# DA1470x register map
Vendor: Dialog; Series: DA1470x; File version: 1.2
CPU: CM33 r0p2, little endian, MPU, FPU, DSP, VTOR, 4 interrupt priority bits
Registers are 32-bit, read-write, reset 0x0 unless marked. A register's access mark holds for its fields unless they carry their own. Offsets are from the block's base; [hi:lo] are bit positions.

## ANAMISC_BIF — ANAMISC_BIF registers
Base 0x50050600
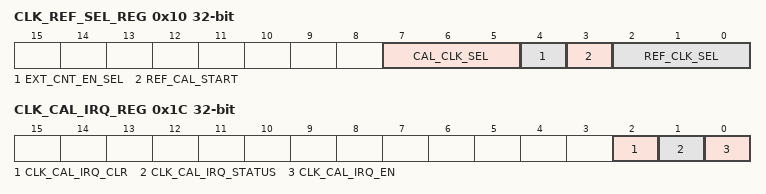
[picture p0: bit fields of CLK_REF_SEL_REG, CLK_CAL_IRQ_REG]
0x10 CLK_REF_SEL_REG — Select clock for oscillator calibration
  [7:5] CAL_CLK_SEL — Select calibration clock input to be used in calibration: 0x0 : DIVN clock 0x1 : RCLP 0x2 : RCHS 0x3 : XTAL32K 0x4 : RCOSC 0x5, 0x6 and 0x7: Reserved
  [4] EXT_CNT_EN_SEL — 0 : Enable XTAL_CNT counter by the REF_CLK selected by REF_CLK_SEL. 1 : Enable XTAL_CNT counter from an external input.
  [3] REF_CAL_START — Writing a '1' starts a calibration. This bit is cleared when calibration is finished, and CLK_REF_VAL is ready.
  [2:0] REF_CLK_SEL — Select reference clock input for calibration: 0x0 : RCLP 0x1 : RCHS 0x2 : XTAL32K 0x3 : RCX 0x4 : RCOSC 0x5 : DIVN clock
0x14 CLK_REF_CNT_REG — Count value for oscillator calibration
  [15:0] REF_CNT_VAL — Indicates the calibration time, with a decrement counter to 1.
0x18 CLK_REF_VAL_REG (reset mask 0x7FFFFFFF) — DIVN reference cycles, lower 16 bits
  [31:0] XTAL_CNT_VAL ro — Returns the number of DIVN clock cycles counted during the calibration time, defined with REF_CNT_VAL
0x1C CLK_CAL_IRQ_REG — Select clock for oscillator calibration
  [2] CLK_CAL_IRQ_CLR — Clear the IRQ. 1: Clear the IRQ 0: No effect. Read out 0 always.
  [1] CLK_CAL_IRQ_STATUS ro — Shows the IRQ bit status.
  [0] CLK_CAL_IRQ_EN — Enable clk calibration IRQ. 0: Disabled. 1*: Enabled. *Note: If IRQ feature is enabled, every calibration should be started by setting CLK_REF_SEL_REG[REF_CAL_START] to 1.

## CRG_AUD — CRG_AUD registers
Base 0x50030000
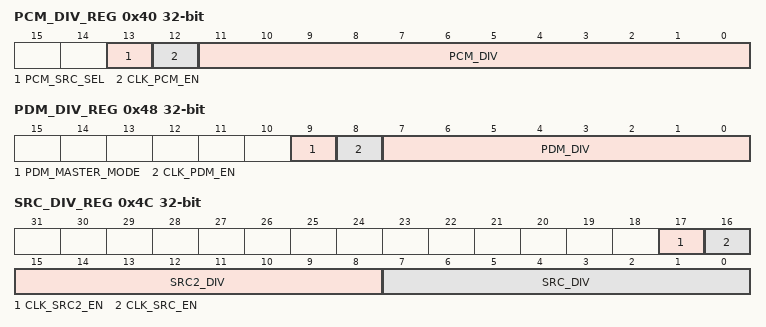
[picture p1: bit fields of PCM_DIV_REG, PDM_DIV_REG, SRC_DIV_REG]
0x40 PCM_DIV_REG — PCM divider and enables
  [13] PCM_SRC_SEL — Selects the clock source 1 = DIV1 clock 0 = DIVN clock
  [12] CLK_PCM_EN — Enable for the internally generated PCM clock The PCM_DIV must be set before or together with CLK_PCM_EN.
  [11:0] PCM_DIV — PCM clock divider. Minimum value is 0x2.
0x44 PCM_FDIV_REG — PCM fractional division register
  [15:0] PCM_FDIV — These bits define the fractional division part of the PCM clock. The left most '1' defines the denominator, the number of '1' bits define the numerator. E.g. 0x0110 means 2/9, with a distribution of 1.0001.0000 0xfeee means 13/16, with a distribution of 1111.1110.1110.1110
0x48 PDM_DIV_REG — PDM divider and enables
  [9] PDM_MASTER_MODE — Master mode selection 0: slave mode 1: master mode
  [8] CLK_PDM_EN — Enable for the internally generated PDM clock The PDM_DIV must be set before or together with CLK_PDM_EN.
  [7:0] PDM_DIV — PDM clock divider
0x4C SRC_DIV_REG — SRC divider and enables
  [17] CLK_SRC2_EN — Enable for the internally generated SRC2 clock The SRC2_DIV must be set before or together with CLK_SRC2_EN.
  [16] CLK_SRC_EN — Enable for the internally generated SRC clock The SRC_DIV must be set before or together with CLK_SRC_EN.
  [15:8] SRC2_DIV — SRC2 clock divider
  [7:0] SRC_DIV — SRC clock divider

## CRG_CTRL — CRG_CTRL registers
Base 0x50060000
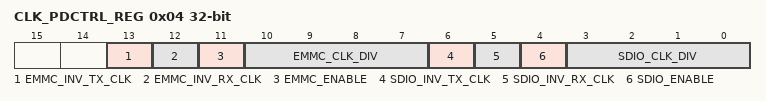
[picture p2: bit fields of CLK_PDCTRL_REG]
0x04 CLK_PDCTRL_REG — Clock control settings for PD_CTRL
  [13] EMMC_INV_TX_CLK — Inverts the clock in the TX path
  [12] EMMC_INV_RX_CLK — Invert the clock in the RX path, cascaded with INV_TX_CLK
  [11] EMMC_ENABLE — Enables the clock.
  [10:7] EMMC_CLK_DIV — clock divider setting 0x0 : divide by 16 0x1 : divide by 1 0x2 : divide by 2 0x4 : divide by 4 0x8 : divide by 8
  [6] SDIO_INV_TX_CLK — Inverts the clock in the TX path
  [5] SDIO_INV_RX_CLK — Invert the clock in the RX path, cascaded with INV_TX_CLK
  [4] SDIO_ENABLE — Enables the clock.
  [3:0] SDIO_CLK_DIV — clock divider setting 0x0 : divide by 16 0x1 : divide by 1 0x2 : divide by 2 0x4 : divide by 4 0x8 : divide by 8
